VERSION ""

NS_ :

BS_:

BU_: RoofPDM VCU
VAL_TABLE_ H_Bridge 1 "H-Bridge" 0 "High Side" ;
VAL_TABLE_ Current_Retry 1 "Manual Reset" 0 "Auto Retry" ;
VAL_TABLE_ Feedback_Type 3 "Current Feedback" 2 "Power Feedback" 1 "Rate Feedback" 0 "Position Feedback" ;
VAL_TABLE_ Diagnostic_bits 3 "Open Circuit" 2 "Overcurrent" 1 "Short Circuit" 0 "No Faults" ;
VAL_TABLE_ Digital_Input 3 "Not Available" 2 "Short to Battery" 1 "Short to Ground" 0 "Open Circuit" ;
VAL_TABLE_ Feedback_ID 134 "Motor Model Configuration" 136 "Channel 7-12 Configuration" 135 "Channel 1-6 Configuration" 133 "Channel 7-12 Feedback" 132 "Channel 1-6 Feedback" 131 "Analog7-8, SW Version" 130 "Analog5-6, Batt Volt, 5V" 129 "Analog3-4, Diagnostic" 128 "Analog1-2, Digital 1-12" ;
VAL_TABLE_ Output_Command_Identifier 7 "Configuration 7-12" 6 "Configuration 1-6" 5 "Command 7-12" 4 "Command 1-6" 0 "Motor Model Configuration" ;

BO_ 2169426478 RoofPDM_Feedback: 8 RoofPDM
 SG_ FBK_Multiplexer M : 63|1@1+ (1,0) [0|0] "" Vector__XXX
 SG_ Current_Ch9 m0 : 32|4@1+ (1,0) [0|15] "" Vector__XXX
 SG_ Current_Ch8 m0 : 28|4@1+ (1,0) [0|15] "" Vector__XXX
 SG_ Current_Ch7 m0 : 24|4@1+ (1,0) [0|15] "" Vector__XXX
 SG_ Current_Ch12 m0 : 44|4@1+ (1,0) [0|15] "" Vector__XXX
 SG_ Current_Ch11 m0 : 40|4@1+ (1,0) [0|15] "" Vector__XXX
 SG_ Current_Ch10 m0 : 36|4@1+ (1,0) [0|15] "" Vector__XXX
 SG_ Current_Ch6 m0 : 20|4@1+ (1,0) [0|15] "" Vector__XXX
 SG_ Current_Ch5 m0 : 16|4@1+ (1,0) [0|15] "" Vector__XXX
 SG_ Current_Ch4 m0 : 12|4@1+ (1,0) [0|15] "" Vector__XXX
 SG_ Current_Ch3 m0 : 8|4@1+ (1,0) [0|15] "" Vector__XXX
 SG_ Current_Ch2 m0 : 4|4@1+ (1,0) [0|15] "" Vector__XXX
 SG_ Current_Ch1 m0 : 0|4@1+ (1,0) [0|15] "" Vector__XXX
 SG_ Diagnostic_9 m1 : 24|3@1+ (1,0) [0|7] "" Vector__XXX
 SG_ Diagnostic_8 m1 : 21|3@1+ (1,0) [0|7] "" Vector__XXX
 SG_ Diagnostic_7 m1 : 18|3@1+ (1,0) [0|7] "" Vector__XXX
 SG_ Diagnostic_6 m1 : 15|3@1+ (1,0) [0|7] "" Vector__XXX
 SG_ Diagnostic_5 m1 : 12|3@1+ (1,0) [0|7] "" Vector__XXX
 SG_ Diagnostic_4 m1 : 9|3@1+ (1,0) [0|7] "" Vector__XXX
 SG_ Diagnostic_3 m1 : 6|3@1+ (1,0) [0|7] "" Vector__XXX
 SG_ Diagnostic_2 m1 : 3|3@1+ (1,0) [0|7] "" Vector__XXX
 SG_ Diagnostic_12 m1 : 33|3@1+ (1,0) [0|7] "" Vector__XXX
 SG_ Diagnostic_11 m1 : 30|3@1+ (1,0) [0|7] "" Vector__XXX
 SG_ Diagnostic_10 m1 : 27|3@1+ (1,0) [0|7] "" Vector__XXX
 SG_ Diagnostic_1 m1 : 0|3@1+ (1,0) [0|7] "" Vector__XXX

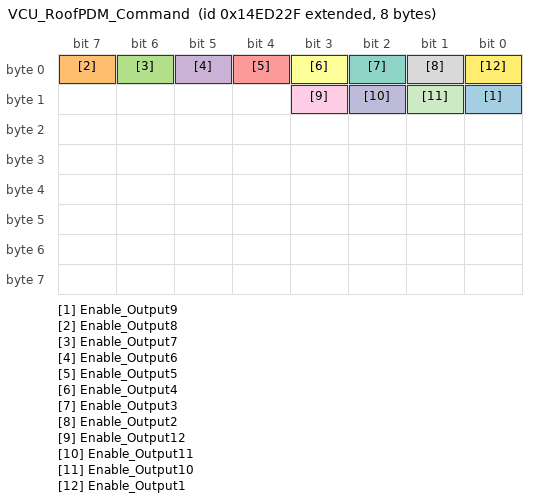
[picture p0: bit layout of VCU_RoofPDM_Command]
BO_ 2169426479 VCU_RoofPDM_Command: 8 VCU
 SG_ Enable_Output9 : 8|1@1+ (1,0) [0|1] "" Vector__XXX
 SG_ Enable_Output8 : 7|1@1+ (1,0) [0|1] "" Vector__XXX
 SG_ Enable_Output7 : 6|1@1+ (1,0) [0|1] "" Vector__XXX
 SG_ Enable_Output6 : 5|1@1+ (1,0) [0|1] "" Vector__XXX
 SG_ Enable_Output5 : 4|1@1+ (1,0) [0|1] "" Vector__XXX
 SG_ Enable_Output4 : 3|1@1+ (1,0) [0|1] "" Vector__XXX
 SG_ Enable_Output3 : 2|1@1+ (1,0) [0|1] "" Vector__XXX
 SG_ Enable_Output2 : 1|1@1+ (1,0) [0|1] "" Vector__XXX
 SG_ Enable_Output12 : 11|1@1+ (1,0) [0|1] "" Vector__XXX
 SG_ Enable_Output11 : 10|1@1+ (1,0) [0|1] "" Vector__XXX
 SG_ Enable_Output10 : 9|1@1+ (1,0) [0|1] "" Vector__XXX
 SG_ Enable_Output1 : 0|1@1+ (1,0) [0|1] "" Vector__XXX

BA_DEF_ SG_  "GenSigSendType" ENUM  "Cyclic","OnWrite","OnWriteWithRepetition","OnChange","OnChangeWithRepetition","IfActive","IfActiveWithRepetition","NoSigSendType";
BA_DEF_ SG_  "GenSigILSupport" ENUM  "No","Yes";
BA_DEF_ SG_  "GenSigEVName" STRING ;
BA_DEF_ SG_  "SigType" ENUM  "Default","Range","RangeSigned","ASCII","Discrete","Control","ReferencePGN","DTC","StringDelimiter","StringLength","StringLengthControl","MessageCounter","MessageChecksum";
BA_DEF_ BO_  "GenMsgCycleTime" INT 0 3600000;
BA_DEF_ BO_  "GenMsgRequestable" INT 0 1;
BA_DEF_ BO_  "GenMsgSendType" ENUM  "cyclic","NotUsed","IfActive","NotUsed","NotUsed","NotUsed","NotUsed","NotUsed","noMsgSendType";
BA_DEF_ BO_  "GenMsgILSupport" ENUM  "No","Yes";
BA_DEF_ BO_  "GenMsgCycleTimeFast" INT 0 3600000;
BA_DEF_ BU_  "NmStationAddress" INT 0 255;
BA_DEF_  "DBName" STRING ;
BA_DEF_  "BusType" STRING ;
BA_DEF_DEF_  "GenSigSendType" "NoSigSendType";
BA_DEF_DEF_  "GenSigILSupport" "Yes";
BA_DEF_DEF_  "GenSigEVName" "Env@Nodename_@Signame";
BA_DEF_DEF_  "SigType" "Default";
BA_DEF_DEF_  "GenMsgCycleTime" 0;
BA_DEF_DEF_  "GenMsgRequestable" 1;
BA_DEF_DEF_  "GenMsgSendType" "noMsgSendType";
BA_DEF_DEF_  "GenMsgILSupport" "Yes";
BA_DEF_DEF_  "GenMsgCycleTimeFast" 0;
BA_DEF_DEF_  "NmStationAddress" 254;
BA_DEF_DEF_  "DBName" "";
BA_DEF_DEF_  "BusType" "CAN";
BA_ "DBName" "Node_IX3212_Roof";
BA_ "NmStationAddress" BU_ RoofPDM 0;
BA_ "NmStationAddress" BU_ VCU 0;
BA_ "GenMsgCycleTimeFast" BO_ 2169426479 100;
BA_ "GenMsgSendType" BO_ 2169426479 0;
BA_ "GenMsgCycleTime" BO_ 2169426479 100;
VAL_ 2169426478 Diagnostic_9 3 "Open Circuit" 2 "Overcurrent" 1 "Short Circuit" 0 "No Faults" ;
VAL_ 2169426478 Diagnostic_8 3 "Open Circuit" 2 "Overcurrent" 1 "Short Circuit" 0 "No Faults" ;
VAL_ 2169426478 Diagnostic_7 3 "Open Circuit" 2 "Overcurrent" 1 "Short Circuit" 0 "No Faults" ;
VAL_ 2169426478 Diagnostic_6 3 "Open Circuit" 2 "Overcurrent" 1 "Short Circuit" 0 "No Faults" ;
VAL_ 2169426478 Diagnostic_5 3 "Open Circuit" 2 "Overcurrent" 1 "Short Circuit" 0 "No Faults" ;
VAL_ 2169426478 Diagnostic_4 3 "Open Circuit" 2 "Overcurrent" 1 "Short Circuit" 0 "No Faults" ;
VAL_ 2169426478 Diagnostic_3 3 "Open Circuit" 2 "Overcurrent" 1 "Short Circuit" 0 "No Faults" ;
VAL_ 2169426478 Diagnostic_2 3 "Open Circuit" 2 "Overcurrent" 1 "Short Circuit" 0 "No Faults" ;
VAL_ 2169426478 Diagnostic_12 3 "Open Circuit" 2 "Overcurrent" 1 "Short Circuit" 0 "No Faults" ;
VAL_ 2169426478 Diagnostic_11 3 "Open Circuit" 2 "Overcurrent" 1 "Short Circuit" 0 "No Faults" ;
VAL_ 2169426478 Diagnostic_10 3 "Open Circuit" 2 "Overcurrent" 1 "Short Circuit" 0 "No Faults" ;
VAL_ 2169426478 Diagnostic_1 3 "Open Circuit" 2 "Overcurrent" 1 "Short Circuit" 0 "No Faults" ;
